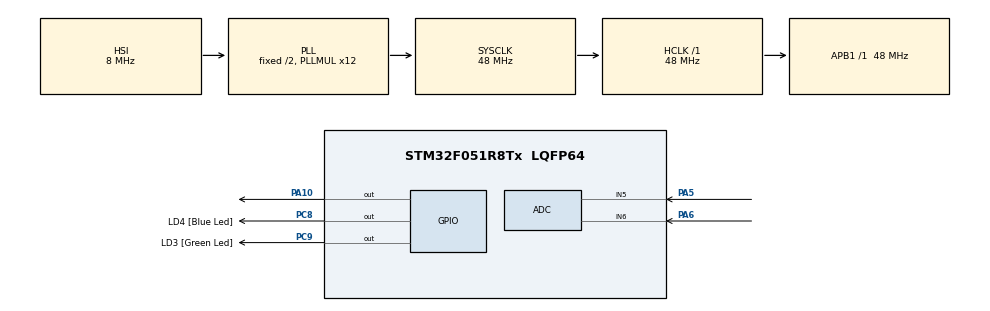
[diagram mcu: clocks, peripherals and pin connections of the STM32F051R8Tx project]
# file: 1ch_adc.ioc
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ADC.ContinuousConvMode=ENABLE
Mcu.Family=STM32F0
Mcu.Name=STM32F051R8Tx
Mcu.Package=LQFP64
PA10.Signal=GPIO_Output
PA13.GPIO_Label=SWDIO
PA13.Mode=Serial_Wire
PA13.Signal=SYS_SWDIO
PA14.GPIO_Label=SWCLK
PA14.Mode=Serial_Wire
PA14.Signal=SYS_SWCLK
PA5.Mode=IN5
PA5.Signal=ADC_IN5
PA6.Mode=IN6
PA6.Signal=ADC_IN6
PC8.GPIO_Label=LD4 [Blue Led]
PC8.Signal=GPIO_Output
PC9.GPIO_Label=LD3 [Green Led]
PC9.Signal=GPIO_Output
ProjectManager.HeapSize=0x200
ProjectManager.StackSize=0x400
ProjectManager.TargetToolchain=STM32CubeIDE
RCC.AHBFreq_Value=48000000
RCC.APB1Freq_Value=48000000
RCC.APB1TimFreq_Value=48000000
RCC.HCLKFreq_Value=48000000
RCC.PLLMUL=RCC_PLL_MUL12
RCC.SYSCLKFreq_VALUE=48000000
RCC.SYSCLKSource=RCC_SYSCLKSOURCE_PLLCLK
board=STM32F0DISCOVERY

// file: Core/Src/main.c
/* USER CODE BEGIN Header */
/**
  ******************************************************************************
  * @file           : main.c
  * @brief          : Main program body
  ******************************************************************************
  * @attention
  *
  * Copyright (c) 2022 STMicroelectronics.
  * All rights reserved.
  *
  * This software is licensed under terms that can be found in the LICENSE file
  * in the root directory of this software component.
  * If no LICENSE file comes with this software, it is provided AS-IS.
  *
  ******************************************************************************
  */
/* USER CODE END Header */
#include "main.h"

ADC_HandleTypeDef hadc;

void SystemClock_Config(void);
static void MX_GPIO_Init(void);
static void MX_ADC_Init(void);

/* USER CODE BEGIN 0 */
uint32_t adcDeger;
uint32_t adcDeger2;
int TotalTime = 0;
int count = 0;
/* USER CODE END 0 */

int main(void)
{

  /* MCU Configuration--------------------------------------------------------*/

  /* Reset of all peripherals, Initializes the Flash interface and the Systick. */
  HAL_Init();

  /* Configure the system clock */
  SystemClock_Config();

  /* Initialize all configured peripherals */
  MX_GPIO_Init();
  MX_ADC_Init();

  /* Infinite loop */
  /* USER CODE BEGIN WHILE */
  while (1)
  {
		HAL_ADC_Start(&hadc);
		adcDeger = HAL_ADC_GetValue(&hadc);
		HAL_Delay(100);
		count = count + 1;

    /* USER CODE END WHILE */

  }
}

void SystemClock_Config(void)
{
  RCC_OscInitTypeDef RCC_OscInitStruct = {0};
  RCC_ClkInitTypeDef RCC_ClkInitStruct = {0};

  /** Initializes the RCC Oscillators according to the specified parameters
  * in the RCC_OscInitTypeDef structure.
  */
  RCC_OscInitStruct.OscillatorType = RCC_OSCILLATORTYPE_HSI|RCC_OSCILLATORTYPE_HSI14;
  RCC_OscInitStruct.HSIState = RCC_HSI_ON;
  RCC_OscInitStruct.HSI14State = RCC_HSI14_ON;
  RCC_OscInitStruct.HSICalibrationValue = RCC_HSICALIBRATION_DEFAULT;
  RCC_OscInitStruct.HSI14CalibrationValue = 16;
  RCC_OscInitStruct.PLL.PLLState = RCC_PLL_ON;
  RCC_OscInitStruct.PLL.PLLSource = RCC_PLLSOURCE_HSI;
  RCC_OscInitStruct.PLL.PLLMUL = RCC_PLL_MUL12;
  RCC_OscInitStruct.PLL.PREDIV = RCC_PREDIV_DIV1;
  if (HAL_RCC_OscConfig(&RCC_OscInitStruct) != HAL_OK)
  {
    Error_Handler();
  }

  /** Initializes the CPU, AHB and APB buses clocks
  */
  RCC_ClkInitStruct.ClockType = RCC_CLOCKTYPE_HCLK|RCC_CLOCKTYPE_SYSCLK
                              |RCC_CLOCKTYPE_PCLK1;
  RCC_ClkInitStruct.SYSCLKSource = RCC_SYSCLKSOURCE_PLLCLK;
  RCC_ClkInitStruct.AHBCLKDivider = RCC_SYSCLK_DIV1;
  RCC_ClkInitStruct.APB1CLKDivider = RCC_HCLK_DIV1;

  if (HAL_RCC_ClockConfig(&RCC_ClkInitStruct, FLASH_LATENCY_1) != HAL_OK)
  {
    Error_Handler();
  }
}

static void MX_ADC_Init(void)
{

  ADC_ChannelConfTypeDef sConfig = {0};

  /** Configure the global features of the ADC (Clock, Resolution, Data Alignment and number of conversion)
  */
  hadc.Instance = ADC1;
  hadc.Init.ClockPrescaler = ADC_CLOCK_ASYNC_DIV1;
  hadc.Init.Resolution = ADC_RESOLUTION_12B;
  hadc.Init.DataAlign = ADC_DATAALIGN_RIGHT;
  hadc.Init.ScanConvMode = ADC_SCAN_DIRECTION_FORWARD;
  hadc.Init.EOCSelection = ADC_EOC_SINGLE_CONV;
  hadc.Init.LowPowerAutoWait = DISABLE;
  hadc.Init.LowPowerAutoPowerOff = DISABLE;
  hadc.Init.ContinuousConvMode = ENABLE;
  hadc.Init.DiscontinuousConvMode = DISABLE;
  hadc.Init.ExternalTrigConv = ADC_SOFTWARE_START;
  hadc.Init.ExternalTrigConvEdge = ADC_EXTERNALTRIGCONVEDGE_NONE;
  hadc.Init.DMAContinuousRequests = DISABLE;
  hadc.Init.Overrun = ADC_OVR_DATA_PRESERVED;
  if (HAL_ADC_Init(&hadc) != HAL_OK)
  {
    Error_Handler();
  }

  /** Configure for the selected ADC regular channel to be converted.
  */
  sConfig.Channel = ADC_CHANNEL_5;
  sConfig.Rank = ADC_RANK_CHANNEL_NUMBER;
  sConfig.SamplingTime = ADC_SAMPLETIME_1CYCLE_5;
  if (HAL_ADC_ConfigChannel(&hadc, &sConfig) != HAL_OK)
  {
    Error_Handler();
  }

  /** Configure for the selected ADC regular channel to be converted.
  */
  sConfig.Channel = ADC_CHANNEL_6;
  if (HAL_ADC_ConfigChannel(&hadc, &sConfig) != HAL_OK)
  {
    Error_Handler();
  }

}

static void MX_GPIO_Init(void)
{
  GPIO_InitTypeDef GPIO_InitStruct = {0};

  /* GPIO Ports Clock Enable */
  __HAL_RCC_GPIOA_CLK_ENABLE();
  __HAL_RCC_GPIOC_CLK_ENABLE();

  /*Configure GPIO pin Output Level */
  HAL_GPIO_WritePin(GPIOC, LD4_Pin|LD3_Pin, GPIO_PIN_RESET);

  /*Configure GPIO pin Output Level */
  HAL_GPIO_WritePin(GPIOA, GPIO_PIN_10, GPIO_PIN_RESET);

  /*Configure GPIO pins : LD4_Pin LD3_Pin */
  GPIO_InitStruct.Pin = LD4_Pin|LD3_Pin;
  GPIO_InitStruct.Mode = GPIO_MODE_OUTPUT_PP;
  GPIO_InitStruct.Pull = GPIO_NOPULL;
  GPIO_InitStruct.Speed = GPIO_SPEED_FREQ_LOW;
  HAL_GPIO_Init(GPIOC, &GPIO_InitStruct);

  /*Configure GPIO pin : PA10 */
  GPIO_InitStruct.Pin = GPIO_PIN_10;
  GPIO_InitStruct.Mode = GPIO_MODE_OUTPUT_PP;
  GPIO_InitStruct.Pull = GPIO_NOPULL;
  GPIO_InitStruct.Speed = GPIO_SPEED_FREQ_LOW;
  HAL_GPIO_Init(GPIOA, &GPIO_InitStruct);

}

void Error_Handler(void)
{
  __disable_irq();
  while (1)
  {
  }
}
